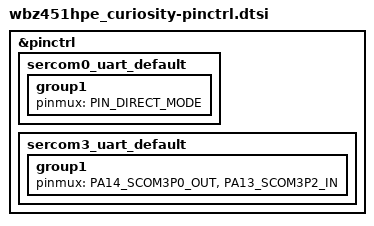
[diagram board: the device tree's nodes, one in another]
/*
 * Copyright (c) 2025 Microchip Technology Inc.
 *
 * SPDX-License-Identifier: Apache-2.0
 */

#include <dt-bindings/pic32c/pic32cx_bz/bz25/pic32cx1012bz25048-pinctrl.h>

&pinctrl {
	sercom0_uart_default: sercom0_uart_default {
		group1 {
			pinmux = <PIN_DIRECT_MODE>;
		};
	};

	sercom3_uart_default: sercom3_uart_default {
		group1 {
			pinmux = <PA14_SCOM3P0_OUT>,
			<PA13_SCOM3P2_IN>;
		};
	};

};
